# YTM32B1MC0 register map
Vendor: YTMicro; File version: 1.0
CPU: CM33 r0p4, little endian, MPU, FPU, 2 interrupt priority bits
Registers are 32-bit, read-write, reset 0x0 unless marked. A register's access mark holds for its fields unless they carry their own. Offsets are from the block's base; [hi:lo] are bit positions; {n}, {i} and the like mark numbered series.

## WDG — Watchdog module
Base 0x4006A000; register names take the prefix WDG_
0x00 SVCR wo — Watchdog Service Code Register
  [15:0] SVCODE — It can be used to service the watchdog or to clear the soft lock bit. Writing 0xB631 followed by 0xC278 will clear the soft lock bit, writing 0xA518 followed by 0xD826 to service the watchdog.
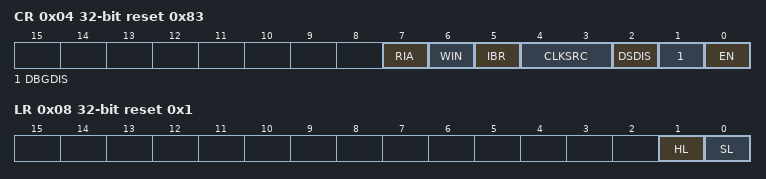
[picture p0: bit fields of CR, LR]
0x04 CR reset 0x83 — Watchdog Control Register
  [7] RIA — Enable reset for invalid APB access.
    0=Generate bus error on invalid APB access; 1=Generate bus error and system reset on invalid APB access
  [6] WIN — Enable window mode.
    0=Disable window mode, watchdog service can be done at any time; 1=Enable window mode, watchdog service is can only be done when timer value is less than the value of WIN register
  [5] IBR — Enable interrupt before reset function
    0=Disable interrupt before reset; 1=Enable interrupt before reset, when watchdog time-out, generate an interrupt first and when next time-out happens, generate reset
  [4:3] CLKSRC
    0=LPO_CLK; 1=SIRC; 2=Functional clock from IPC
  [2] DSDIS — Enable or disable watchdog in deepsleep mode
    0=Enable watchdog in deepsleep mode; 1=Disable watchdog in deepsleep mode
  [1] DBGDIS — Enable or disable watchdog in debug mode.
    0=Enable watchdog in debug mode; 1=Disable watchdog in debug mode
  [0] EN — Enable watchdog module.
    0=Disable watchdog module; 1=Enable watchdog module
0x08 LR reset 0x1 — Watchdog Lock Register
  [1] HL — Hard lock, when this bit set, the CR, WIN, TO are read-only. once set, the bit can only be clear by reset.
  [0] SL — Soft lock, when this bit set, the CR, WIN, TO are read-only. this bit can be clear by writing a valid sequence to SVR register.
0x0C TOVR reset 0xC00 — Watchdog Timer Overflow Value
  [15:0] TO — A 16bit down counter uses this value to start count. Writing value should be greater than 0x100. Otherwise 0x100 is written to this register.
0x10 WVR
  [15:0] WIN — When CR[WIN] is set, the window mode is enabled, the service sequence can only be written when the timer value is less than the value of this register.
0x14 CNTCVR ro — Watchdog Counter Current Value Register
  [15:0] CVAL — Watchdog counter current value.
0x18 INTF — Watchdog Interrupt Flag register
  [0] IF — Watchdog interrupt flag. Write 1 to this field to clear the flag and interrupt.
    0=No watchdog interrupt is pending; 1=Watchdog timer time-out interrupt is pending

## EWDG0 — External Watchdog
Base 0x4006B000; register names take the prefix EWDG0_
0x00 SERV — The SERV register is write only and reads of this register return zero.
  [7:0] SERVICE — The EWDG refresh mechanism requires the CPU to write two values to the SERV register: a first data byte of 0xA8, followed by a second data byte of 0x6C. The EWDG refresh is invalid if either of the following conditions is true. The first or second data byte is not written correctly. The second data byte is not written within 63 peripheral bus cycles of the first data byte.
0x04 CMPL wo — The CMPL register is write once register and is reset to zero after reset.
  [15:0] COMPAREL rw — Low value of EWDG counter compare.
0x08 CMPH wo reset 0xFFFF — The CMPH register is write once register and is reset to 0xFFFF after reset.
  [15:0] COMPAREH rw — High value of EWDG counter compare. The max value of COMPAREH is 0xFFFE because the EWDG will never expires if it is 0xFFFF.
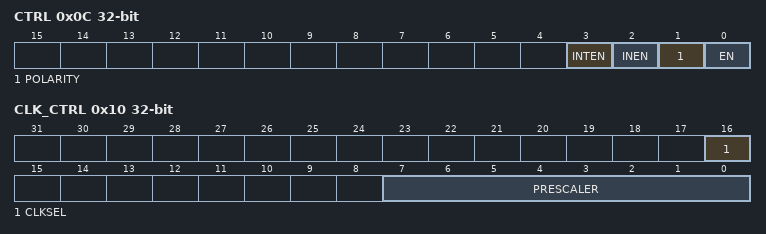
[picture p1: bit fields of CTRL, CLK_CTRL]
0x0C CTRL — This register contains the control bits for EWDG. ote{INEN, POLARITY and EN bits can be written once after a CPU reset. Modifying these bits more than once, generates a bus transfer error.}
  [3] INTEN — This bit when set and EWDG_OUT_b is asserted, an interrupt request is generated. To de-assert interrupt request, user should clear this bit by writing 0.
    0=No EWDG interrupt occurs; 1=EWDG interrupt occurs
  [2] INEN — Enable EWDG_IN pin.
    0=Disable EWDG_IN pin; 1=Enable EWDG_IN pin
  [1] POLARITY — Control the polarity of EWDG_IN pin
    0=input EWDG_IN pin directly; 1=input inverted EWDG_IN pin
  [0] EN — When this bit is set, EWDG module is enabled. When this bit is set at first time, the EWDG counter is reset to zero and EWDG_OUT_b is deasserted. This bit is write once, clearing this bit makes it disable and cannot be re-enabled until next chip reset.
    0=Disable EWDG module; 1=Enable EWDG module
0x10 CLK_CTRL — This register contains the bits to control the clock source for running EWDG. Write the required prescaler value before enabling the EWDG. ote{This register can be written only once after a CPU reset. Writing this register more than once generates a bus transfer error.}
  [16] CLKSEL — Select EWDG functional clock source
    0=SIRC; 1=LPO_CLK
  [7:0] PRESCALER
